# STM32H503 register map
File version: 1.5
CPU: CM33 r0p0, little endian, MPU, FPU, 4 interrupt priority bits
Registers are 32-bit, read-write, reset 0x0 unless marked. A register's access mark holds for its fields unless they carry their own. Offsets are from the block's base; [hi:lo] are bit positions; 'fields as' and 'values as' point back to an identical list.

## RCC (part 2 of 2) — Reset and clock controller
Base 0x44020C00
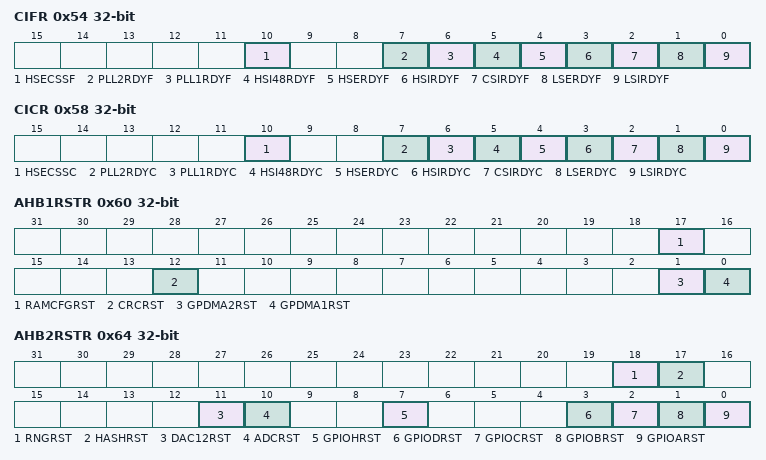
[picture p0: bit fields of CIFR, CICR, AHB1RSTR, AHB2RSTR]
0x54 CIFR ro — RCC clock source interrupt flag register
  [10] HSECSSF — HSE clock security system interrupt flag Reset by software by writing HSECSSC bit. Set by hardware in case of HSE clock failure.
    0=NoInterrupt (No clock security interrupt caused by HSE clock failure); 1=Interrupt (Clock security interrupt caused by HSE clock failure)
  [7] PLL2RDYF — PLL2 ready interrupt flag Reset by software by writing PLL2RDYC bit. Set by hardware when the PLL2 locks and PLL2RDYIE is set.
    0=NotInterrupted (No clock ready interrupt); 1=Interrupted (Clock ready interrupt)
  [6] PLL1RDYF — PLL1 ready interrupt flag Reset by software by writing PLL1RDYC bit. Set by hardware when the PLL1 locks and PLL1RDYIE is set.
    values as PLL2RDYF
  [5] HSI48RDYF — HSI48 ready interrupt flag Reset by software by writing HSI48RDYC bit. Set by hardware when the HSI48 clock becomes stable and HSI48RDYIE is set.
    values as PLL2RDYF
  [4] HSERDYF — HSE ready interrupt flag Reset by software by writing HSERDYC bit. Set by hardware when the HSE clock becomes stable and HSERDYIE is set.
    values as PLL2RDYF
  [3] HSIRDYF — HSI ready interrupt flag Reset by software by writing HSIRDYC bit. Set by hardware when the HSI clock becomes stable and HSIRDYIE is set.
    values as PLL2RDYF
  [2] CSIRDYF — CSI ready interrupt flag Reset by software by writing CSIRDYC bit. Set by hardware when the CSI clock becomes stable and CSIRDYIE is set.
    values as PLL2RDYF
  [1] LSERDYF — LSE ready interrupt flag Reset by software by writing LSERDYC bit. Set by hardware when the LSE clock becomes stable and LSERDYIE is set.
    values as PLL2RDYF
  [0] LSIRDYF — LSI ready interrupt flag Reset by software by writing LSIRDYC bit. Set by hardware when the LSI clock becomes stable and LSIRDYIE is set.
    values as PLL2RDYF
0x58 CICR — RCC clock source interrupt clear register
  [all] fields
    1=Clear interrupt flag
  [10] HSECSSC — HSE clock security system interrupt clear Set by software to clear HSECSSF. Reset by hardware when clear done.
  [7] PLL2RDYC — PLL2 ready interrupt clear Set by software to clear PLL2RDYF. Reset by hardware when clear done.
  [6] PLL1RDYC — PLL1 ready interrupt clear Set by software to clear PLL1RDYF. Reset by hardware when clear done.
  [5] HSI48RDYC — HSI48 ready interrupt clear Set by software to clear HSI48RDYF. Reset by hardware when clear done.
  [4] HSERDYC — HSE ready interrupt clear Set by software to clear HSERDYF. Reset by hardware when clear done.
  [3] HSIRDYC — HSI ready interrupt clear Set by software to clear HSIRDYF. Reset by hardware when clear done.
  [2] CSIRDYC — HSI ready interrupt clear Set by software to clear CSIRDYF. Reset by hardware when clear done.
  [1] LSERDYC — LSE ready interrupt clear Set by software to clear LSERDYF. Reset by hardware when clear done.
  [0] LSIRDYC — LSI ready interrupt clear Set by software to clear LSIRDYF. Reset by hardware when clear done.
0x60 AHB1RSTR — RCC AHB1 reset register
  [all] fields
    1=Reset the selected module
  [17] RAMCFGRST — RAMCFG block reset Set and reset by software.
  [12] CRCRST — CRC block reset Set and reset by software.
  [1] GPDMA2RST — GPDMA2 block reset Set and reset by software.
  [0] GPDMA1RST — GPDMA1 block reset Set and reset by software.
0x64 AHB2RSTR — RCC AHB2 peripheral reset register
  [all] fields
    1=Reset the selected module
  [18] RNGRST — RNG block reset Set and reset by software.
  [17] HASHRST — HASH block reset Set and reset by software.
  [11] DAC12RST — DAC block reset Set and reset by software.
  [10] ADCRST — ADC block reset
  [7] GPIOHRST — GPIOH block reset Set and reset by software.
  [3] GPIODRST — GPIOD block reset Set and reset by software.
  [2] GPIOCRST — GPIOC block reset Set and reset by software.
  [1] GPIOBRST — GPIOB block reset Set and reset by software.
  [0] GPIOARST — GPIOA block reset Set and reset by software.
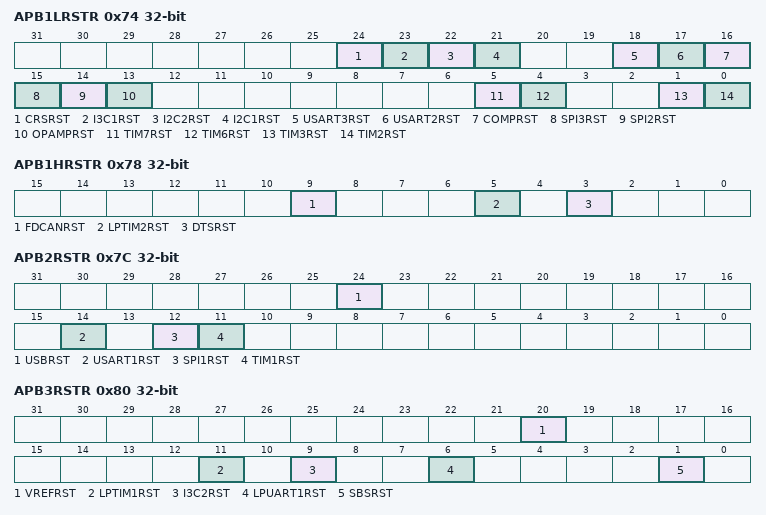
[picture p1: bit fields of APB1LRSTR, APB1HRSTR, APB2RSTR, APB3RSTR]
0x74 APB1LRSTR — RCC APB1 peripheral low reset register
  [all] fields
    1=Reset the selected module
  [24] CRSRST — CRS block reset Set and reset by software.
  [23] I3C1RST — I3C1 block reset Set and reset by software.
  [22] I2C2RST — I2C2 block reset Set and reset by software.
  [21] I2C1RST — I2C1 block reset Set and reset by software.
  [18] USART3RST — USART3 block reset Set and reset by software.
  [17] USART2RST — USART2 block reset Set and reset by software.
  [16] COMPRST — COMP block reset Set and reset by software.
  [15] SPI3RST — SPI3 block reset Set and reset by software.
  [14] SPI2RST — SPI2 block reset Set and reset by software.
  [13] OPAMPRST — OPAMP block reset Set and reset by software.
  [5] TIM7RST — TIM7 block reset Set and reset by software.
  [4] TIM6RST — TIM6 block reset Set and reset by software.
  [1] TIM3RST — TIM3 block reset Set and reset by software.
  [0] TIM2RST — TIM2 block reset Set and reset by software.
0x78 APB1HRSTR — RCC APB1 peripheral high reset register
  [all] fields
    1=Reset the selected module
  [9] FDCANRST — FDCAN block reset
  [5] LPTIM2RST — LPTIM2 block reset Set and reset by software.
  [3] DTSRST — DTS block reset Set and reset by software.
0x7C APB2RSTR — RCC APB2 peripheral reset register
  [all] fields
    1=Reset the selected module
  [24] USBRST — USB block reset
  [14] USART1RST — USART1 block reset Set and reset by software.
  [12] SPI1RST — SPI1 block reset Set and reset by software.
  [11] TIM1RST — TIM1 block reset Set and reset by software.
0x80 APB3RSTR — RCC APB3 peripheral reset register
  [all] fields
    1=Reset the selected module
  [20] VREFRST — VREF block reset Set and reset by software.
  [11] LPTIM1RST — LPTIM1 block reset Set and reset by software.
  [9] I3C2RST — I3C2RST block reset Set and reset by software.
  [6] LPUART1RST — LPUART1 block reset Set and reset by software.
  [1] SBSRST — SBS block reset Set and reset by software.
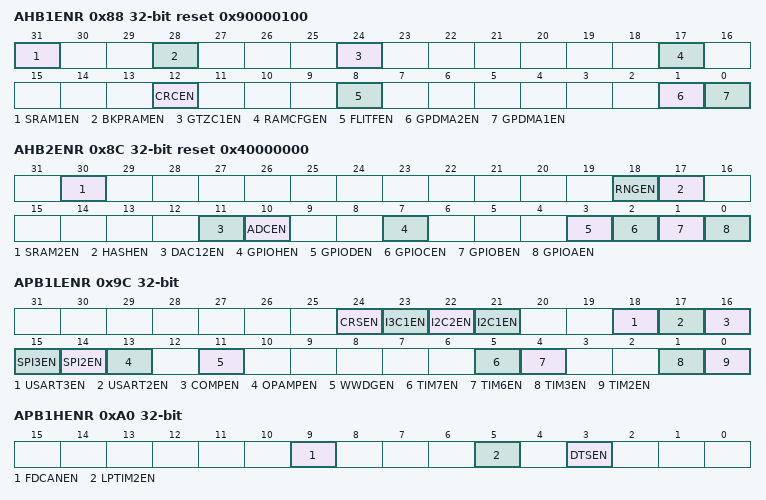
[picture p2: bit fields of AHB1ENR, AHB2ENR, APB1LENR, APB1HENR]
0x88 AHB1ENR reset 0x90000100 — RCC AHB1 peripherals clock register
  [all] fields
    0=Disabled (The selected clock is disabled); 1=Enabled (The selected clock is enabled)
  [31] SRAM1EN — SRAM1 clock enable Set and reset by software.
  [28] BKPRAMEN — BKPRAM clock enable Set and reset by software
  [24] GTZC1EN — GTZC1 clock enable
  [17] RAMCFGEN — RAMCFG clock enable Set and reset by software.
  [12] CRCEN — CRC clock enable Set and reset by software.
  [8] FLITFEN — Flash interface clock enable Set and reset by software.
  [1] GPDMA2EN — GPDMA2 clock enable Set and reset by software.
  [0] GPDMA1EN — GPDMA1 clock enable Set and reset by software.
0x8C AHB2ENR reset 0x40000000 — RCC AHB2 peripheral clock register
  [all] fields
    values as the fields of AHB1ENR
  [30] SRAM2EN — SRAM2 clock enable Set and reset by software.
  [18] RNGEN — RNG clock enable Set and reset by software.
  [17] HASHEN — HASH clock enable Set and reset by software.
  [11] DAC12EN — DAC clock enable Set and reset by software.
  [10] ADCEN — ADC peripherals clock enabled
  [7] GPIOHEN — GPIOH clock enable Set and reset by software.
  [3] GPIODEN — GPIOD clock enable Set and reset by software.
  [2] GPIOCEN — GPIOC clock enable Set and reset by software.
  [1] GPIOBEN — GPIOB clock enable Set and reset by software.
  [0] GPIOAEN — GPIOA clock enable Set and reset by software.
0x9C APB1LENR — RCC APB1 peripheral clock register
  [all] fields
    values as the fields of AHB1ENR
  [24] CRSEN — CRS clock enable Set and reset by software.
  [23] I3C1EN — I3C1 clock enable Set and reset by software.
  [22] I2C2EN — I2C2 clock enable Set and reset by software.
  [21] I2C1EN — I2C1 clock enable Set and reset by software.
  [18] USART3EN — USART3 clock enable Set and reset by software.
  [17] USART2EN — USART2 clock enable Set and reset by software.
  [16] COMPEN — COMP clock enable Set and reset by software.
  [15] SPI3EN — SPI3 clock enable Set and reset by software.
  [14] SPI2EN — SPI2 clock enable Set and reset by software.
  [13] OPAMPEN — OPAMP clock enable Set and reset by software.
  [11] WWDGEN — WWDG clock enable Set and reset by software.
  [5] TIM7EN — TIM7 clock enable Set and reset by software.
  [4] TIM6EN — TIM6 clock enable Set and reset by software.
  [1] TIM3EN — TIM3 clock enable Set and reset by software.
  [0] TIM2EN — TIM2 clock enable Set and reset by software.
0xA0 APB1HENR — RCC APB1 peripheral clock register
  [all] fields
    values as the fields of AHB1ENR
  [9] FDCANEN — FDCAN peripheral clock enable
  [5] LPTIM2EN — LPTIM2 clock enable Set and reset by software.
  [3] DTSEN — DTS clock enable Set and reset by software.
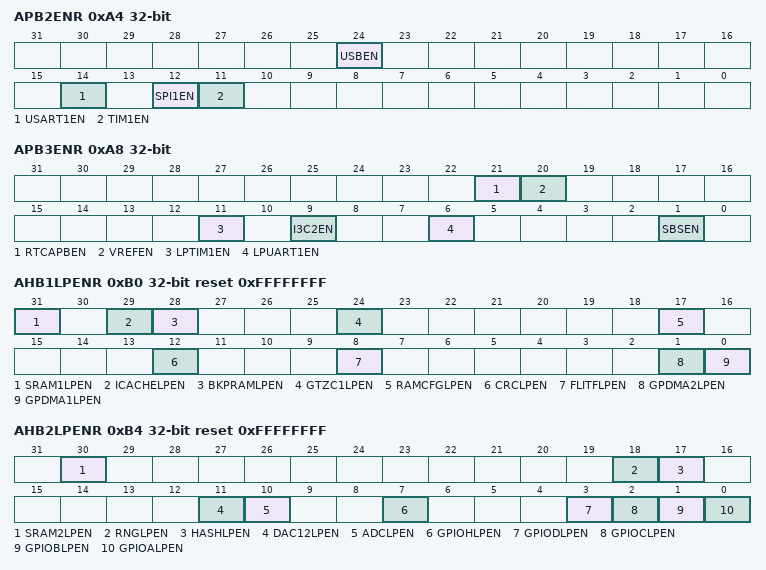
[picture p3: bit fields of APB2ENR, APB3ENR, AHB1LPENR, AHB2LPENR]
0xA4 APB2ENR — RCC APB2 peripheral clock register
  [all] fields
    values as the fields of AHB1ENR
  [24] USBEN — USB clock enable
  [14] USART1EN — USART1 clock enable Set and reset by software.
  [12] SPI1EN — SPI1 clock enable Set and reset by software.
  [11] TIM1EN — TIM1 clock enable Set and reset by software.
0xA8 APB3ENR — RCC APB3 peripheral clock register
  [all] fields
    values as the fields of AHB1ENR
  [21] RTCAPBEN — RTC APB interface clock enable Set and reset by software.
  [20] VREFEN — VREF clock enable Set and reset by software.
  [11] LPTIM1EN — LPTIM1 clock enable Set and reset by software.
  [9] I3C2EN — I3C2EN clock enable Set and reset by software.
  [6] LPUART1EN — LPUART1 clock enable Set and reset by software.
  [1] SBSEN — SBS clock enable Set and reset by software.
0xB0 AHB1LPENR reset 0xFFFFFFFF — RCC AHB1 sleep clock register
  [all] fields
    0=Disabled (The selected clock is disabled during csleep mode); 1=Enabled (The selected clock is enabled during csleep mode)
  [31] SRAM1LPEN — SRAM1 clock enable during sleep mode Set and reset by software
  [29] ICACHELPEN — ICACHE clock enable during sleep mode Set and reset by software
  [28] BKPRAMLPEN — BKPRAM clock enable during sleep mode Set and reset by software
  [24] GTZC1LPEN — GTZC1 clock enable during sleep mode
  [17] RAMCFGLPEN — RAMCFG clock enable during sleep mode Set and reset by software.
  [12] CRCLPEN — CRC clock enable during sleep mode Set and reset by software.
  [8] FLITFLPEN — Flash interface (FLITF) clock enable during sleep mode Set and reset by software.
  [1] GPDMA2LPEN — GPDMA2 clock enable during sleep mode Set and reset by software.
  [0] GPDMA1LPEN — GPDMA1 clock enable during sleep mode Set and reset by software.
0xB4 AHB2LPENR reset 0xFFFFFFFF — RCC AHB2 sleep clock register
  [all] fields
    values as the fields of AHB1LPENR
  [30] SRAM2LPEN — SRAM2 clock enable during sleep mode Set and reset by software.
  [18] RNGLPEN — RNG clock enable during sleep mode Set and reset by software.
  [17] HASHLPEN — HASH clock enable during sleep mode Set and reset by software.
  [11] DAC12LPEN — DAC clock enable during sleep mode Set and reset by software.
  [10] ADCLPEN — ADC peripherals clock enable during sleep mode
  [7] GPIOHLPEN — GPIOH clock enable during sleep mode Set and reset by software.
  [3] GPIODLPEN — GPIOD clock enable during sleep mode Set and reset by software.
  [2] GPIOCLPEN — GPIOC clock enable during sleep mode Set and reset by software.
  [1] GPIOBLPEN — GPIOB clock enable during sleep mode Set and reset by software.
  [0] GPIOALPEN — GPIOA clock enable during sleep mode Set and reset by software.
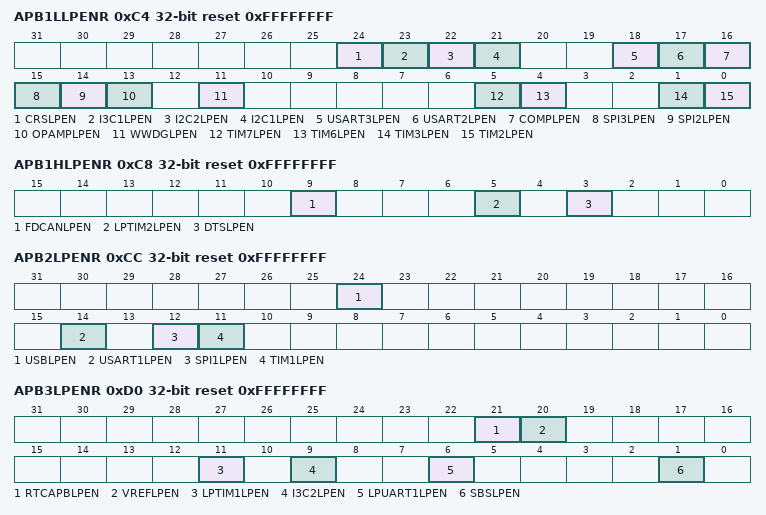
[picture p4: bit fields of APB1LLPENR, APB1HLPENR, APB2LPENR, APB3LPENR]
0xC4 APB1LLPENR reset 0xFFFFFFFF — RCC APB1 sleep clock register
  [all] fields
    values as the fields of AHB1LPENR
  [24] CRSLPEN — CRS clock enable during sleep mode Set and reset by software.
  [23] I3C1LPEN — I3C1 clock enable during sleep mode Set and reset by software.
  [22] I2C2LPEN — I2C2 clock enable during sleep mode Set and reset by software.
  [21] I2C1LPEN — I2C1 clock enable during sleep mode Set and reset by software.
  [18] USART3LPEN — USART3 clock enable during sleep mode Set and reset by software.
  [17] USART2LPEN — USART2 clock enable during sleep mode Set and reset by software.
  [16] COMPLPEN — COMP clock enable during sleep mode Set and reset by software.
  [15] SPI3LPEN — SPI3 clock enable during sleep mode Set and reset by software.
  [14] SPI2LPEN — SPI2 clock enable during sleep mode Set and reset by software.
  [13] OPAMPLPEN — OPAMP clock enable during sleep mode Set and reset by software.
  [11] WWDGLPEN — WWDG clock enable during sleep mode Set and reset by software.
  [5] TIM7LPEN — TIM7 clock enable during sleep mode Set and reset by software.
  [4] TIM6LPEN — TIM6 clock enable during sleep mode Set and reset by software.
  [1] TIM3LPEN — TIM3 clock enable during sleep mode Set and reset by software.
  [0] TIM2LPEN — TIM2 clock enable during sleep mode Set and reset by software.
0xC8 APB1HLPENR reset 0xFFFFFFFF — RCC APB1 sleep clock register
  [all] fields
    values as the fields of AHB1LPENR
  [9] FDCANLPEN — FDCAN peripheral clock enable during sleep mode
  [5] LPTIM2LPEN — LPTIM2 clock enable during sleep mode Set and reset by software.
  [3] DTSLPEN — DTS clock enable during sleep mode Set and reset by software.
0xCC APB2LPENR reset 0xFFFFFFFF — RCC APB2 sleep clock register
  [all] fields
    values as the fields of AHB1LPENR
  [24] USBLPEN — USB clock enable during sleep mode
  [14] USART1LPEN — USART1 clock enable during sleep mode Set and reset by software.
  [12] SPI1LPEN — SPI1 clock enable during sleep mode Set and reset by software.
  [11] TIM1LPEN — TIM1 clock enable during sleep mode Set and reset by software.
0xD0 APB3LPENR reset 0xFFFFFFFF — RCC APB3 sleep clock register
  [all] fields
    values as the fields of AHB1LPENR
  [21] RTCAPBLPEN — RTC APB interface clock enable during sleep mode Set and reset by software.
  [20] VREFLPEN — VREF clock enable during sleep mode Set and reset by software.
  [11] LPTIM1LPEN — LPTIM1 clock enable during sleep mode Set and reset by software.
  [9] I3C2LPEN — I3C2 clock enable during sleep mode Set and reset by software.
  [6] LPUART1LPEN — LPUART1 clock enable during sleep mode Set and reset by software.
  [1] SBSLPEN — SBS clock enable during sleep mode Set and reset by software.
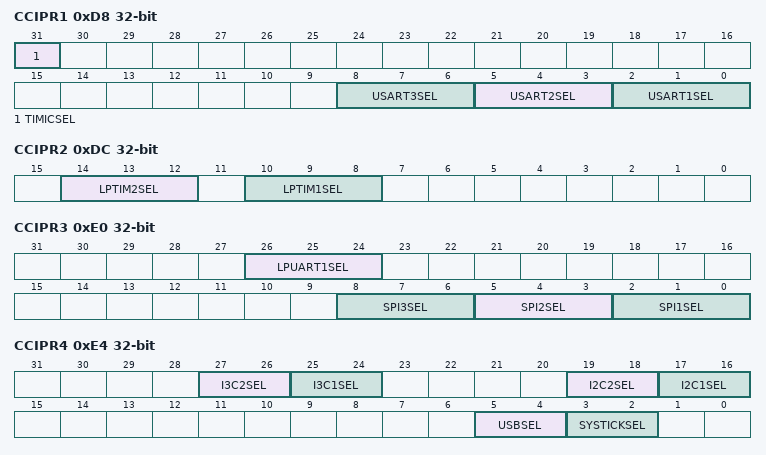
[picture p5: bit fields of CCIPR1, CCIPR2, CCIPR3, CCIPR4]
0xD8 CCIPR1 — RCC kernel clock configuration register
  [31] TIMICSEL — TIM2, TIM3 and LPTIM2 input capture source selection Set and reset by software.
    0=Disabled (No internal clock available for timers input capture); 1=Enabled (hsi_ker_ck/1024, hsi_ker_ck/8 and csi_ker_ck/128 selected for timers input capture)
  [8:6] USART3SEL — USART3 kernel clock source selection Set and reset by software. others: reserved, the kernel clock is disabled
    0=PCLK (Peripheral bus clock used as selected as clock source (rcc_pclk_x)); 1=PLL2_Q (PLL2 Q clock selected as clock source (pll2_q_ck)); 3=HSI_KER (HSI kernel clock selected as clock source (hsi_ker_ck)); 4=CSI_KER (CSI kernel clock selected as clock source (csi_ker_ck)); 5=LSE (LSE clock selected as clock source (lse_ck))
  [5:3] USART2SEL — USART2 kernel clock source selection Set and reset by software. others: reserved, the kernel clock is disabled
    values as USART3SEL
  [2:0] USART1SEL — USART1 kernel clock source selection Set and reset by software. others: reserved, the kernel clock is disabled
    values as USART3SEL
0xDC CCIPR2 — RCC kernel clock configuration register
  [14:12] LPTIM2SEL — LPTIM2 kernel clock source selection others: reserved, the kernel clock is disabled
    0=PCLK (Peripheral bus clock used as selected as clock source (rcc_pclk_x)); 1=PLL2_P (PLL2 P clock selected as clock source (pll2_p_ck)); 3=LSE_KER (LSE kernel selected as clock source (lse_ck)); 4=LSI_KER (LSI kernel selected as clock source (lsi_ker_ck)); 5=PER_CK (per_ck clock selected as clock source)
  [10:8] LPTIM1SEL — LPTIM1 kernel clock source selection others: reserved, the kernel clock is disabled
    values as LPTIM2SEL
0xE0 CCIPR3 — RCC kernel clock configuration register
  [26:24] LPUART1SEL — LPUART1 kernel clock source selection others: reserved, the kernel clock is disabled
    values as CCIPR1.USART3SEL
  [8:6] SPI3SEL — SPI3 kernel clock source selection Set and reset by software. others: reserved, the kernel clock is disabled
    0=PLL1_Q (PLL1 Q clock selected as clock source (pll1_q_ck)); 1=PLL2_P (PLL2 P clock selected as clock source (pll2_p_ck)); 3=AUDIOCLK (AUDIOCLK clock selected as clock source); 4=PER_CK (per_ck clock selected as clock source)
  [5:3] SPI2SEL — SPI2 kernel clock source selection Set and reset by software. others: reserved, the kernel clock is disabled
    values as SPI3SEL
  [2:0] SPI1SEL — SPI1 kernel clock source selection Set and reset by software. others: reserved, the kernel clock is disabled
    values as SPI3SEL
0xE4 CCIPR4 — RCC kernel clock configuration register
  [27:26] I3C2SEL — I3C2 kernel clock source selection
    0=PCLK (Peripheral bus clock used as selected as clock source (rcc_pclk_x)); 1=PLL2_R (PLL2 R clock selected as clock source (pll2_r_ck)); 2=HSI_KER (HSI kernel clock selected as clock source (hsi_ker_ck))
  [25:24] I3C1SEL — I3C1 kernel clock source selection
    values as I3C2SEL
  [19:18] I2C2SEL — I2C2 kernel clock source selection
    0=PCLK (Peripheral bus clock used as selected as clock source (rcc_pclk_x)); 1=PLL2_R (PLL2 R Clock selected as clock source (pll2_r_ck)); 2=HSI_KER (HSI kernel clock selected as clock source (hsi_ker_ck)); 3=CSI_KER (CSI kernel clock selected as clock source (csi_ker_ck))
  [17:16] I2C1SEL — I2C1 kernel clock source selection
    values as I2C2SEL
  [5:4] USBSEL — USB kernel clock source selection
    0=DISABLE (Disable the clock); 1=PLL1_Q (PLL1 Q clock selected as clock source (pll1_q_ck)); 2=PLL2_Q (PLL2 Q clock selected as clock source (pll2_q_ck)); 3=HSI48 (HSI48 clock selected as clock source (hsi48_ker_ck))
  [3:2] SYSTICKSEL — SYSTICK clock source selection Note: rcc_hclk frequency must be four times higher than lsi_ker_ck/lse_ck (period (LSI/LSE) greater than or equal 4 * period (HCLK).
    0=HCLK_DIV8 (RCC HLCK divided by 8 selected as clock source (rcc_hclk / 8)); 1=LSI_KER (LSI kernel selected as clock source (lsi_ker_ck)); 2=LSE (LSE selected as clock source (lse_ck))
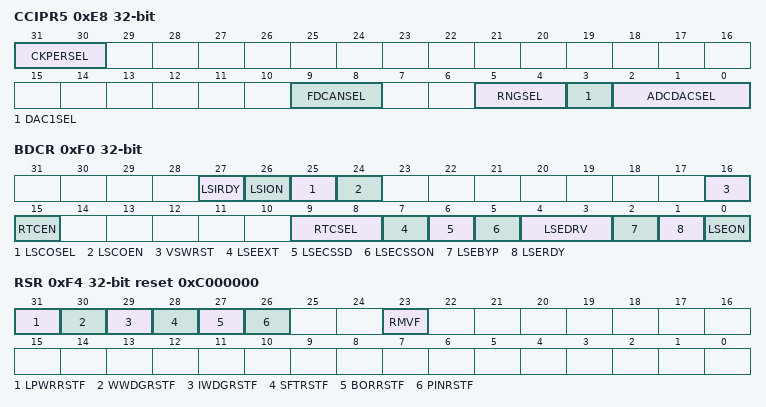
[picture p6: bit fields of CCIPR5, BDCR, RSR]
0xE8 CCIPR5 — RCC kernel clock configuration register
  [31:30] CKPERSEL — per_ck clock source selection
    0=HSI_KER (HSI kernel clock selected as clock source (hsi_ker_ck)); 1=CSI_KER (CSI kernel clock selected as clock source (csi_ker_ck)); 2=HSE (HSE clock selected as clock source (hse_ck))
  [9:8] FDCANSEL — FDCAN kernel clock source selection
    0=HSE (HSE clock selected as clock source (hse_ck)); 1=PLL1_Q (PLL1 Q clock selected as clock source (pll1_q_ck)); 2=PLL2_Q (PLL2 Q clock selected as clock source (pll2_q_ck))
  [5:4] RNGSEL — RNG kernel clock source selection
    0=HSI48_KER (HSI48 kernel clock selected as clock source (hsi48_ker_ck)); 1=PLL1_Q (PLL1 Q clock selected as clock source (pll1_q_ck)); 2=LSE (LSE clock selected as clock source (lse_ck)); 3=LSI (LSI kernel clock selected as clock source (lsi_ker_ck))
  [3] DAC1SEL — DAC1 sample and hold clock source selection
    0=LSE (LSE selected as clock source (lse_ck)); 1=LSI_KER (LSI kernel selected as clock source (lsi_ker_ck))
  [2:0] ADCDACSEL — ADC and DAC kernel clock source selection others: reserved, the kernel clock is disabled
    0=HCLK (HLCK clock selected as clock source (rcc_hclk)); 1=SYS (System clock selected as pclock source (sys_ck)); 2=PLL2_R (PLL2 R clock selected as clock source (pll2_r_ck)); 3=HSE (HSE clock selected as clock source (hse_ck)); 4=HSI_KER (HSI kernel clock selected as clock source (hsi_ker_ck)); 5=CSI_KER (CSI kernel clock selected as clock source (csi_ker_ck))
0xF0 BDCR — RCC Backup domain control register
  [27] LSIRDY — LSI oscillator ready Set and cleared by hardware to indicate when the LSI oscillator is stable. After the LSION bit is cleared, LSIRDY goes low after three internal low-speed oscillator clock cycles. This bit is set when the LSI is used by IWDG or RTC, even if LSION = 0.
    on read: 0=NotReady (Clock not ready); 1=Ready (Clock ready)
  [26] LSION — LSI oscillator enable Set and cleared by software.
    0=Disabled (Oscillator disabled); 1=Enabled (Oscillator enabled)
  [25] LSCOSEL — Low-speed clock output selection Set and cleared by software.
    0=LSI (LSI clock selected); 1=LSE (LSE clock selected)
  [24] LSCOEN — Low-speed clock output (LSCO) enable Set and cleared by software.
  [16] VSWRST — VSwitch domain software reset Set and reset by software.
    0=NotActivated (Reset not activated); 1=Resets the entire VSW domain
  [15] RTCEN — RTC clock enable Set and reset by software.
    0=Disabled (RTC clock disabled); 1=Enabled (RTC clock enabled)
  [9:8] RTCSEL — RTC clock source selection Set by software to select the clock source for the RTC. These bits can be written only one time (except in case of failure detection on LSE). These bits must be written before LSECSSON is enabled. The VSWRST bit can be used to reset them, then it can be written one time again. If HSE is selected as RTC clock, this clock is lost when the system is in Stop mode or in case of a pin reset (NRST).
    0=NoClock; 1=LSE (LSE oscillator clock used as RTC clock); 2=LSI (LSI oscillator clock used as RTC clock); 3=HSE (HSE oscillator clock divided by a prescaler used as RTC clock)
  [7] LSEEXT — low-speed external clock type in bypass mode Set and reset by software to select the external clock type (analog or digital). The external clock must be enabled with the LSEON bit, to be used by the device. The LSEEXT bit can be written only if the LSE oscillator is disabled.
    0=Analog (HSE in analog mode); 1=Digital (HSE in digital mode)
  [6] LSECSSD — LSE clock security system failure detection Set by hardware to indicate when a failure has been detected by the clock security system on the external 32 kHz oscillator.
    on read: 0=No failure detected on 32 kHz oscillator; 1=Failure detected on 32 kHz oscillator
  [5] LSECSSON — LSE clock security system enable Set by software to enable the clock security system on 32 kHz oscillator. LSECSSON must be enabled after LSE is enabled (LSEON enabled) and ready (LSERDY set by hardware) and after RTCSEL is selected. Once enabled, this bit cannot be disabled, except after a LSE failure detection (LSECSSD = 1). In that case the software must disable LSECSSON.
    0=SecurityOff (Clock security system on 32 kHz oscillator off); 1=SecurityOn (Clock security system on 32 kHz oscillator on)
  [4:3] LSEDRV — LSE oscillator driving capability Set by software to select the driving capability of the LSE oscillator. These bit can be written only if LSE oscillator is disabled (LSEON = 0 and LSERDY = 0).
    0=Lowest LSE oscillator driving capability; 1=Medium low LSE oscillator driving capability; 2=Medium high LSE oscillator driving capability; 3=Highest LSE oscillator driving capability
  [2] LSEBYP — LSE oscillator bypass Set and reset by software to bypass oscillator in debug mode. This bit must not be written when the LSE is enabled (by LSEON) or ready (LSERDY = 1)
    0=NotBypassed (LSE crystal oscillator not bypassed); 1=Bypassed (LSE crystal oscillator bypassed with external clock)
  [1] LSERDY — LSE oscillator ready Set and reset by hardware to indicate when the LSE is stable. This bit needs 6 cycles of lse_ck clock to fall down after LSEON has been set to 0.
    on read: 0=NotReady (LSE oscillator not ready); 1=Ready (LSE oscillator ready)
  [0] LSEON — LSE oscillator enabled Set and reset by software.
    0=Off (LSE oscillator Off); 1=On (LSE oscillator On)
0xF4 RSR reset 0xC000000 — RCC reset status register
  [31] LPWRRSTF — Low-power reset flag Set by hardware when a reset occurs due to Stop or Standby mode entry, whereas the corresponding nRST_STOP, nRST_STBY option bit is cleared. Cleared by writing to the RMVF bit.
    on read: 0=No reset occurred for block; 1=Reset occurred for block
  [30] WWDGRSTF — window watchdog reset flag Reset by software by writing the RMVF bit. Set by hardware when a window watchdog reset occurs.
    values as LPWRRSTF
  [29] IWDGRSTF — independent watchdog reset flag Reset by software by writing the RMVF bit. Set by hardware when an independent watchdog reset occurs.
    values as LPWRRSTF
  [28] SFTRSTF — system reset from CPU reset flag Reset by software by writing the RMVF bit. Set by hardware when the system reset is due to CPU.The CPU can generate a system reset by writing SYSRESETREQ bit of AIRCR register of the core M33.
    values as LPWRRSTF
  [27] BORRSTF — BOR reset flag Reset by software by writing the RMVF bit. Set by hardware when a BOR reset occurs (pwr_bor_rst).
    values as LPWRRSTF
  [26] PINRSTF — pin reset flag (NRST) Reset by software by writing the RMVF bit. Set by hardware when a reset from pin occurs.
    values as LPWRRSTF
  [23] RMVF — remove reset flag Set and reset by software to reset the value of the reset flags.
    0=NotActivated (Reset not activated); 1=Reset the reset status flags
0x114 PRIVCFGR — RCC privilege configuration register
  [1] PRIV — RCC functions privilege configuration
    0=Any (RCC functions can be modified by privileged or unprivileged access); 1=PrivilegedOnly (RCC functions can only be modified by privileged access)
